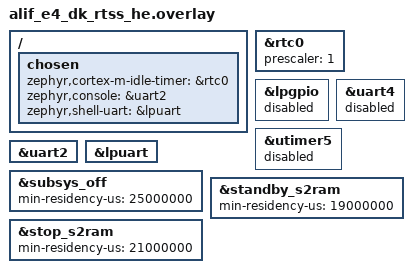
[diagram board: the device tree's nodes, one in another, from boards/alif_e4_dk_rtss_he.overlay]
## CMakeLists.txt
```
#
# Copyright (C) 2024  Alif Semiconductor
#
# SPDX-License-Identifier: Apache-2.0
#

cmake_minimum_required(VERSION 3.20.0)
find_package(Zephyr REQUIRED HINTS $ENV{ZEPHYR_BASE})
project(alif_system_off)

target_sources(app PRIVATE src/main.c)
```

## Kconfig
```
# Copyright (C) 2024 Alif Semiconductor - All Rights Reserved.
# Use, distribution and modification of this code is permitted under the
# terms stated in the Alif Semiconductor Software License Agreement
#
# You should have received a copy of the Alif Semiconductor Software
# License Agreement with this file. If not, please write to:
# contact@alifsemi.com, or visit: https://alifsemi.com/license


mainmenu "Alif Power Management States Demo"

source "Kconfig.zephyr"
```

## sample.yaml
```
sample:
  name: Alif Power Management States Demo
  description: >
    Demonstrates Zephyr power management states (PM_STATE_RUNTIME_IDLE,
    PM_STATE_SUSPEND_TO_IDLE, PM_STATE_SUSPEND_TO_RAM, PM_STATE_SOFT_OFF)
    for Alif RTSS cores.  The PM states exercised are driven by capability
    predicates (S2RAM_SUPPORTED / SOFT_OFF_SUPPORTED) rather than core type,
    and are selected via build snippets: pm-system-off-s2ram-tcm (HE TCM
    retention), pm-system-off-mram (MRAM boot SOFT_OFF, HE or HP), and
    pm-system-off-s2ram-sram0 (SRAM0 retention S2RAM, E8 only, HE or HP).
common:
  tags:
    - power
    - pm
    - counter
    - rtc
    - drivers
  filter: SOC_FAMILY_ENSEMBLE or SOC_FAMILY_BALLETTO
  harness: console
  harness_config:
    type: multi_line
    regex:
      - "PM states demo"
      - "POWER STATE SEQUENCE"
tests:
  sample.pm.system_off.s2ram_tcm:
    platform_allow:
      - alif_e7_dk_rtss_he
      - alif_e1c_dk_rtss_he
      - alif_b1_dk_rtss_he
      - alif_e8_dk_rtss_he
    integration_platforms:
      - alif_e7_dk_rtss_he
    depends_on:
      - counter
    extra_args:
      - SNIPPET=pm-system-off-s2ram-tcm
  sample.pm.system_off.mram:
    platform_allow:
      - alif_e7_dk_rtss_he
      - alif_e7_dk_rtss_hp
      - alif_e8_dk_rtss_he
      - alif_e8_dk_rtss_hp
      - alif_e1c_dk_rtss_he
      - alif_b1_dk_rtss_he
    integration_platforms:
      - alif_e7_dk_rtss_he
      - alif_e7_dk_rtss_hp
    depends_on:
      - counter
    extra_args:
      - SNIPPET=pm-system-off-mram
  sample.pm.system_off.s2ram_sram0:
    platform_allow:
      - alif_e8_dk_rtss_he
      - alif_e8_dk_rtss_hp
    integration_platforms:
      - alif_e8_dk_rtss_he
    depends_on:
      - counter
    extra_args:
      - SNIPPET=pm-system-off-s2ram-sram0
```

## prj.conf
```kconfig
CONFIG_PM=y
CONFIG_PM_DEVICE=y
CONFIG_POWER_DOMAIN=y
#CONFIG_POWEROFF=y
CONFIG_IDLE_STACK_SIZE=1024
CONFIG_SYS_CLOCK_TICKS_PER_SEC=1000

CONFIG_COUNTER=y

CONFIG_STDOUT_CONSOLE=y
CONFIG_PRINTK=y
CONFIG_ASSERT=y

# Logging Configuration - Only for this application
CONFIG_LOG=y
CONFIG_LOG_DEFAULT_LEVEL=0
CONFIG_LOG_MODE_DEFERRED=y
CONFIG_LOG_PROCESS_THREAD_SLEEP_MS=5
CONFIG_LOG_BACKEND_UART=y
```

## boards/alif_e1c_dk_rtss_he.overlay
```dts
/* Copyright (C) 2024 Alif Semiconductor - All Rights Reserved.
 * Use, distribution and modification of this code is permitted under the
 * terms stated in the Alif Semiconductor Software License Agreement
 *
 * You should have received a copy of the Alif Semiconductor Software
 * License Agreement with this file. If not, please write to:
 * contact@alifsemi.com, or visit: https: //alifsemi.com/license
 *
 */

&rtc0 {
	prescaler = <1>;
	status = "okay";
};

&lpgpio {
	status = "disabled";
};

&uart4 {
	status = "disabled";
};

&uart2 {
	status = "okay";
};

&lpuart {
	status = "okay";
};

&subsys_off {
	min-residency-us = <25000000>;
	status = "okay";
};

&standby_s2ram {
	min-residency-us = <19000000>;
	status = "okay";
};

&stop_s2ram {
	min-residency-us = <21000000>;
	status = "okay";
};

/ {
	chosen {
		zephyr,cortex-m-idle-timer = &rtc0;
		zephyr,console = &uart2;
		zephyr,shell-uart = &lpuart;
	};
};
```

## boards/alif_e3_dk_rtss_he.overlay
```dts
/*
 * Copyright (c) 2024 Alif Semiconductor
 * SPDX-License-Identifier: Apache-2.0
 */

/*
 * By default, the core boots from ITCM. Enable the below node to boot
 * from MRAM. Please make sure to use the same address in the json file
 * while flashing the binary using SE tools.
 */
/*
&itcm {
	reg = < 0x80000000 DT_SIZE_K(1024) >;
	itcm_global_base = < 0x80000000 >;
};
*/

/*
 * Enable RTC and Set the counter to increment every 1sec
 */
&rtc0 {
	prescaler = < 32768 >;
	status = "okay";
};
```

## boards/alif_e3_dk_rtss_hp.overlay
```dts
/* Copyright (C) 2025 Alif Semiconductor - All Rights Reserved.
 * Use, distribution and modification of this code is permitted under the
 * terms stated in the Alif Semiconductor Software License Agreement
 *
 * You should have received a copy of the Alif Semiconductor Software
 * License Agreement with this file. If not, please write to:
 * contact@alifsemi.com, or visit: https: //alifsemi.com/license
 *
 */

&timer0 {
	status = "okay";
};

&lpgpio {
	status = "disabled";
};

&uart4 {
	status = "disabled";
};

&utimer5 {
	status = "disabled";
};

&uart2 {
	status = "okay";
};

&subsys_off {
	min-residency-us = <25000000>;
	status = "okay";
};

/ {
	chosen {
		zephyr,console = &uart2;
	};
};
```

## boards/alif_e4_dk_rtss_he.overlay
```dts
/* Copyright (C) 2024 Alif Semiconductor - All Rights Reserved.
 * Use, distribution and modification of this code is permitted under the
 * terms stated in the Alif Semiconductor Software License Agreement
 *
 * You should have received a copy of the Alif Semiconductor Software
 * License Agreement with this file. If not, please write to:
 * contact@alifsemi.com, or visit: https: //alifsemi.com/license
 *
 */

&rtc0 {
	prescaler = <1>;
	status = "okay";
};

&lpgpio {
	status = "disabled";
};

&uart4 {
	status = "disabled";
};

&utimer5 {
	status = "disabled";
};

&uart2 {
	status = "okay";
};

&lpuart {
	status = "okay";
};

&subsys_off {
	min-residency-us = <25000000>;
	status = "okay";
};

&standby_s2ram {
	min-residency-us = <19000000>;
	status = "okay";
};

&stop_s2ram {
	min-residency-us = <21000000>;
	status = "okay";
};

/ {
	chosen {
		zephyr,cortex-m-idle-timer = &rtc0;
		zephyr,console = &uart2;
		zephyr,shell-uart = &lpuart;
	};
};
```

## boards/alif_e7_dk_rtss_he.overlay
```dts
/* Copyright (C) 2024 Alif Semiconductor - All Rights Reserved.
 * Use, distribution and modification of this code is permitted under the
 * terms stated in the Alif Semiconductor Software License Agreement
 *
 * You should have received a copy of the Alif Semiconductor Software
 * License Agreement with this file. If not, please write to:
 * contact@alifsemi.com, or visit: https: //alifsemi.com/license
 *
 */

/*
 * Enable RTC and Set the counter to increment every 1sec
 */
&rtc0 {
	prescaler = < 32768 >;
	status = "okay";
};
```

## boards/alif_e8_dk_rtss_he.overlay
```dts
/* Copyright (C) 2025 Alif Semiconductor - All Rights Reserved.
 * Use, distribution and modification of this code is permitted under the
 * terms stated in the Alif Semiconductor Software License Agreement
 *
 * You should have received a copy of the Alif Semiconductor Software
 * License Agreement with this file. If not, please write to:
 * contact@alifsemi.com, or visit: https: //alifsemi.com/license
 *
 */

&rtc0 {
	prescaler = <1>;
	status = "okay";
};

&lpgpio {
	status = "disabled";
};

&uart4 {
	status = "disabled";
};

&utimer5 {
	status = "disabled";
};

&uart2 {
	status = "okay";
};

&lpuart {
	status = "okay";
};

&subsys_off {
	min-residency-us = <25000000>;
	status = "okay";
};

&standby_s2ram {
	min-residency-us = <19000000>;
	status = "okay";
};

&stop_s2ram {
	min-residency-us = <21000000>;
	status = "okay";
};

/ {
	chosen {
		zephyr,cortex-m-idle-timer = &rtc0;
		zephyr,console = &uart2;
		zephyr,shell-uart = &lpuart;
	};
};
```

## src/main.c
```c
/* Copyright (C) 2024 Alif Semiconductor - All Rights Reserved.
 * Use, distribution and modification of this code is permitted under the
 * terms stated in the Alif Semiconductor Software License Agreement
 *
 * You should have received a copy of the Alif Semiconductor Software
 * License Agreement with this file. If not, please write to:
 * contact@alifsemi.com, or visit: https: //alifsemi.com/license
 *
 */

#include <stdio.h>
#include <zephyr/kernel.h>
#include <zephyr/device.h>
#include <zephyr/init.h>
#include <zephyr/pm/pm.h>
#include <zephyr/pm/policy.h>
#if defined(CONFIG_POWEROFF)
#include <zephyr/sys/poweroff.h>
#endif
#include <zephyr/drivers/counter.h>
#include <zephyr/sys/util.h>

#include <zephyr/logging/log.h>
LOG_MODULE_REGISTER(pm_system_off, LOG_LEVEL_INF);

/* Set to 1 to dump full NVIC ISPR state on wakeup */
#define APP_PM_WAKEUP_DEBUG 0

#if DT_NODE_HAS_COMPAT_STATUS(DT_NODELABEL(rtc0), snps_dw_apb_rtc, okay)
	#define WAKEUP_SOURCE DT_NODELABEL(rtc0)
#elif DT_NODE_HAS_COMPAT_STATUS(DT_NODELABEL(timer0), snps_dw_timers, okay)
	#define WAKEUP_SOURCE DT_NODELABEL(timer0)
#else
#error "Wakeup Device not enabled in the dts"
#endif


/*
 * Sleep duration constants for each PM state.
 *
 * Upper bound: at 400 MHz, ticks to cycles calculation in PM driver
 * overflows uint32 max for values > 10.7s (2^32 / 400). All deep-sleep
 * durations and overlay min-residency-us values must stay below this ceiling.
 */
/* Sleep duration for PM_STATE_RUNTIME_IDLE */
#define RUNTIME_IDLE_SLEEP_USEC (18 * 1000 * 1000)
/* Sleep duration for PM_STATE_SUSPEND_TO_IDLE */
#define SUSPEND_IDLE_SLEEP_USEC (10 * 1000)
/* Sleep duration for PM_STATE_SUSPEND_TO_RAM substate 0 (STANDBY) */
#define S2RAM_STANDBY_SLEEP_USEC (6 * 1000 * 1000)
/* Sleep duration for PM_STATE_SUSPEND_TO_RAM substate 1 (STOP) */
#define S2RAM_STOP_SLEEP_USEC (9 * 1000 * 1000)
/* Sleep duration for PM_STATE_SOFT_OFF */
#define SOFT_OFF_SLEEP_USEC (10 * 1000 * 1000)
/* Wakeup duration for sys_poweroff (permanent power off) */
#define POWEROFF_WAKEUP_USEC (10 * 1000 * 1000)

/*
 * MRAM base address - used to determine boot location
 * TCM boot: VTOR = 0x0
 * MRAM boot: VTOR >= 0x80000000
 */
#define MRAM_BASE_ADDRESS 0x80000000

#define IS_BOOTING_FROM_MRAM() (SCB->VTOR >= MRAM_BASE_ADDRESS)

/*
 * True when the DTS chosen zephyr,sram points at sram0. The snippet overlay
 * is responsible for ensuring SRAM0 has retention support on the target board.
 */
#if DT_NODE_EXISTS(DT_NODELABEL(sram0)) && DT_HAS_CHOSEN(zephyr_sram)
#define IS_SRAM0_CONFIGURED_AS_RAM() \
	DT_SAME_NODE(DT_CHOSEN(zephyr_sram), DT_NODELABEL(sram0))
#else
#define IS_SRAM0_CONFIGURED_AS_RAM() 0
#endif

/*
 * S2RAM_SUPPORTED — retention-capable sleep is possible when:
 *   - SRAM0 is the configured data RAM (HE or HP, E8 only), OR
 *   - HE core booting from TCM (TCM has hardware retention)
 *
 * SOFT_OFF_SUPPORTED — mutually exclusive with S2RAM: used when no
 * retained RAM is available (HP-TCM, HE-MRAM boot without SRAM0).
 */
#define S2RAM_SUPPORTED \
	(IS_SRAM0_CONFIGURED_AS_RAM() || \
	 (IS_ENABLED(CONFIG_RTSS_HE) && !IS_BOOTING_FROM_MRAM()))

#define SOFT_OFF_SUPPORTED (!S2RAM_SUPPORTED)

/* Validate ordering of deep-sleep durations at compile time */
BUILD_ASSERT(S2RAM_STOP_SLEEP_USEC > S2RAM_STANDBY_SLEEP_USEC,
	"STOP sleep duration must be greater than STANDBY sleep duration");
BUILD_ASSERT(SOFT_OFF_SLEEP_USEC > S2RAM_STOP_SLEEP_USEC,
	"SOFT_OFF sleep duration must be greater than STOP sleep duration");

/**
 * Helper function to lock/unlock deeper power states.
 * @param lock true → lock all deep states (allow RUNTIME_IDLE only)
 *             false → unlock the applicable state; keep the other locked
 */
static void app_pm_lock_deeper_states(bool lock)
{
	if (lock) {
		/*
		 * Lock both deep states unconditionally so PM policy cannot
		 * accidentally enter them during the RUNTIME_IDLE phase, where
		 * the 18 s sleep exceeds the reduced min-residency values.
		 */
		pm_policy_state_lock_get(PM_STATE_SUSPEND_TO_RAM, PM_ALL_SUBSTATES);
		pm_policy_state_lock_get(PM_STATE_SOFT_OFF,       PM_ALL_SUBSTATES);
	} else if (S2RAM_SUPPORTED) {
		pm_policy_state_lock_put(PM_STATE_SUSPEND_TO_RAM, PM_ALL_SUBSTATES);
		/* SOFT_OFF stays locked for the entire demo */
	} else {
		pm_policy_state_lock_put(PM_STATE_SOFT_OFF, PM_ALL_SUBSTATES);
		/* S2RAM stays locked for the entire demo */
	}
}

/*
 * This function will be invoked in the PRE_KERNEL_2 phase of the init routine.
 */
static int app_pre_kernel_init(void)
{
	/* Lock deeper power states to allow only RUNTIME_IDLE */
	app_pm_lock_deeper_states(true);

	return 0;
}
SYS_INIT(app_pre_kernel_init, PRE_KERNEL_2, 0);

#if !defined(CONFIG_CORTEX_M_SYSTICK_LPM_TIMER_COUNTER)
static volatile uint32_t alarm_cb_status;
static void alarm_callback_fn(const struct device *wakeup_dev,
				uint8_t chan_id, uint32_t ticks,
				void *user_data)
{
	LOG_DBG("%s: Alarm triggered", wakeup_dev->name);
	alarm_cb_status = 1;
}
#endif

static int app_enter_normal_sleep(uint32_t sleep_usec)
{
#if defined(CONFIG_CORTEX_M_SYSTICK_LPM_TIMER_COUNTER)
	k_sleep(K_USEC(sleep_usec));
#else
	const struct device *const wakeup_dev = DEVICE_DT_GET(WAKEUP_SOURCE);
	struct counter_alarm_cfg alarm_cfg;
	int ret;

	alarm_cfg.flags = 0;
	alarm_cfg.ticks = counter_us_to_ticks(wakeup_dev, sleep_usec);
	alarm_cfg.callback = alarm_callback_fn;
	alarm_cfg.user_data = &alarm_cfg;

	ret = counter_set_channel_alarm(wakeup_dev, 0, &alarm_cfg);
	if (ret) {
		LOG_ERR("Could not set the alarm");
		return ret;
	}
	LOG_DBG("Set alarm for %u microseconds", sleep_usec);

	k_sleep(K_USEC(sleep_usec));

	if (!alarm_cb_status) {
		return -1;
	}
	alarm_cb_status = 0;


#endif
	return 0;
}

#if !defined(CONFIG_POWEROFF)
static int app_enter_deep_sleep(uint32_t sleep_usec)
{
#if defined(CONFIG_CORTEX_M_SYSTICK_LPM_TIMER_COUNTER)
	/**
	 * Set a delay more than the min-residency-us configured so that
	 * the sub-system will go to OFF state.
	 */
	k_sleep(K_USEC(sleep_usec));
#else
	const struct device *const wakeup_dev = DEVICE_DT_GET(WAKEUP_SOURCE);
	struct counter_alarm_cfg alarm_cfg = {0};
	int ret;
	/*
	 * Set the alarm and delay so that idle thread can run
	 */
	alarm_cfg.ticks = counter_us_to_ticks(wakeup_dev, sleep_usec);
	alarm_cfg.callback = alarm_callback_fn;
	ret = counter_set_channel_alarm(wakeup_dev, 0, &alarm_cfg);
	if (ret) {
		LOG_ERR("Failed to set the alarm (err %d)", ret);
		return ret;
	}

	LOG_DBG("Set alarm for %u microseconds", sleep_usec);
	/*
	 * Wait for the alarm to trigger. The idle thread will
	 * take care of entering the deep sleep state via PM framework.
	 */
	k_sleep(K_USEC(sleep_usec));
#endif

	return 0;
}
#endif /* !CONFIG_POWEROFF */

/* PM state name lookup for notifier logging */
static const char * const pm_state_names[] = {
	[PM_STATE_ACTIVE]          = "ACTIVE",
	[PM_STATE_RUNTIME_IDLE]    = "RUNTIME_IDLE",
	[PM_STATE_SUSPEND_TO_IDLE] = "SUSPEND_TO_IDLE",
	[PM_STATE_STANDBY]         = "STANDBY",
	[PM_STATE_SUSPEND_TO_RAM]  = "SUSPEND_TO_RAM",
	[PM_STATE_SUSPEND_TO_DISK] = "SUSPEND_TO_DISK",
	[PM_STATE_SOFT_OFF]        = "SOFT_OFF",
};

#define PM_STATE_STR(s) \
	((s) < ARRAY_SIZE(pm_state_names) ? pm_state_names[(s)] : "UNKNOWN")

static void pm_notify_entry(enum pm_state state)
{
	const struct pm_state_info *info = pm_state_next_get(0);
	uint8_t substate_id = info ? info->substate_id : 0U;

	LOG_INF("PM enter: %s (substate %u)", PM_STATE_STR(state), substate_id);
}

/*
 * With CONFIG_LOG_MODE_DEFERRED, LOG_INF here only writes to the ring buffer
 * — no UART access — so this is safe even before devices are resumed.
 */
static void pm_notify_pre_resume(enum pm_state state)
{
	const struct pm_state_info *info = pm_state_next_get(0);
	uint8_t substate_id = info ? info->substate_id : 0U;
	uint32_t active_exc = SCB->ICSR & SCB_ICSR_VECTACTIVE_Msk;

	if (active_exc >= 16U) {
		LOG_INF("PM wakeup: %s (substate %u) IRQ %u",
			PM_STATE_STR(state), substate_id, active_exc - 16U);
	} else if (active_exc != 0U) {
		LOG_INF("PM wakeup: %s (substate %u) exception %u",
			PM_STATE_STR(state), substate_id, active_exc);
	} else {
		LOG_INF("PM wakeup: %s (substate %u)",
			PM_STATE_STR(state), substate_id);
	}
#if APP_PM_WAKEUP_DEBUG
	for (int i = 0; i < 16; i++) {
		if (NVIC->ISPR[i]) {
			LOG_INF("PM wakeup: NVIC ISPR[%d] = 0x%08x", i, NVIC->ISPR[i]);
		}
	}
#endif
}

static void pm_notify_exit(enum pm_state state)
{
	const struct pm_state_info *info = pm_state_next_get(0);
	uint8_t substate_id = info ? info->substate_id : 0U;

	LOG_INF("PM exit:  %s (substate %u)", PM_STATE_STR(state), substate_id);
}

static struct pm_notifier app_pm_notifier = {
	.state_entry       = pm_notify_entry,
	.pre_device_resume = pm_notify_pre_resume,
	.state_exit        = pm_notify_exit,
};

int main(void)
{
	const struct device *const cons = DEVICE_DT_GET(DT_CHOSEN(zephyr_console));
	const struct device *const wakeup_dev = DEVICE_DT_GET(WAKEUP_SOURCE);
	int ret;

	__ASSERT(device_is_ready(cons), "%s: device not ready", cons->name);
	__ASSERT(device_is_ready(wakeup_dev), "%s: device not ready", wakeup_dev->name);

	pm_notifier_register(&app_pm_notifier);

	if (S2RAM_SUPPORTED) {
		LOG_INF("%s (S2RAM): PM states demo "
			"(RUNTIME_IDLE, SUSPEND_TO_IDLE, S2RAM STANDBY, S2RAM STOP)",
			CONFIG_BOARD);
	} else {
		LOG_INF("%s (SOFT_OFF): PM states demo "
			"(RUNTIME_IDLE, SUSPEND_TO_IDLE, SOFT_OFF)",
			CONFIG_BOARD);
	}

	ret = counter_start(wakeup_dev);
	__ASSERT(!ret || ret == -EALREADY, "Failed to start counter (err %d)", ret);

	LOG_INF("POWER STATE SEQUENCE:");
#if defined(CONFIG_POWEROFF)
	LOG_INF("  1. PM_STATE_RUNTIME_IDLE");
	LOG_INF("  2. PM_STATE_SUSPEND_TO_IDLE");
	LOG_INF("  3. Power off (sys_poweroff)");
#else
	LOG_INF("  1. PM_STATE_RUNTIME_IDLE");
	LOG_INF("  2. PM_STATE_SUSPEND_TO_IDLE");
	if (S2RAM_SUPPORTED) {
		LOG_INF("  3. PM_STATE_SUSPEND_TO_RAM (substate 0: STANDBY)");
		LOG_INF("  4. PM_STATE_SUSPEND_TO_RAM (substate 1: STOP)");
	} else {
		LOG_INF("  3. PM_STATE_SOFT_OFF");
	}
#endif

	/* Lock SUSPEND_IDLE to force PM policy to select RUNTIME_IDLE only */
	pm_policy_state_lock_get(PM_STATE_SUSPEND_TO_IDLE, PM_ALL_SUBSTATES);
	LOG_INF("Enter RUNTIME_IDLE sleep for (%d microseconds)", RUNTIME_IDLE_SLEEP_USEC);
	ret = app_enter_normal_sleep(RUNTIME_IDLE_SLEEP_USEC);
	__ASSERT(ret == 0, "Could not enter RUNTIME_IDLE sleep (err %d)", ret);

	LOG_INF("Exited from RUNTIME_IDLE sleep");
	pm_policy_state_lock_put(PM_STATE_SUSPEND_TO_IDLE, PM_ALL_SUBSTATES);

#if defined(CONFIG_CORTEX_M_SYSTICK_LPM_TIMER_COUNTER)
	LOG_INF("Enter PM_STATE_SUSPEND_TO_IDLE for (%d microseconds)",
		SUSPEND_IDLE_SLEEP_USEC);
	k_sleep(K_USEC(SUSPEND_IDLE_SLEEP_USEC));
	LOG_INF("Exited from PM_STATE_SUSPEND_TO_IDLE");
	pm_policy_state_lock_get(PM_STATE_SUSPEND_TO_IDLE, PM_ALL_SUBSTATES);
#else
	/* Lock SUSPEND_TO_IDLE when LPM timer support is not configured */
	pm_policy_state_lock_get(PM_STATE_SUSPEND_TO_IDLE, PM_ALL_SUBSTATES);
	LOG_INF("PM_STATE_SUSPEND_TO_IDLE (skipped - LPM timer not enabled)");
#endif

#if defined(CONFIG_POWEROFF)
	/* Configure wakeup source for permanent power off */
	struct counter_alarm_cfg alarm_cfg;

	LOG_INF("=== Enter (sys_poweroff) ===");
	LOG_INF("System will power off and can only wake via external event (RTC/Timer)");
	k_sleep(K_SECONDS(2));

	/* Set alarm for wakeup from power off */
	alarm_cfg.ticks = counter_us_to_ticks(wakeup_dev, POWEROFF_WAKEUP_USEC);
	ret = counter_set_channel_alarm(wakeup_dev, 0, &alarm_cfg);
	if (ret) {
		LOG_ERR("Failed to set wakeup alarm (err %d)", ret);
	} else {
		LOG_INF("Wakeup alarm set for %u seconds", POWEROFF_WAKEUP_USEC / 1000000);
	}

	LOG_INF("Calling sys_poweroff() - system will power off permanently");
	sys_poweroff();

	/* Should never reach here */
	LOG_ERR("Failed to execute sys_poweroff()");

	return -1;
#else
	/* Unlock deeper power states to allow S2RAM and/or SOFT_OFF */
	app_pm_lock_deeper_states(false);

	if (S2RAM_SUPPORTED) {
		LOG_INF("Enter PM_STATE_SUSPEND_TO_RAM (substate 0: STANDBY) for (%d microseconds)",
			S2RAM_STANDBY_SLEEP_USEC);
		ret = app_enter_deep_sleep(S2RAM_STANDBY_SLEEP_USEC);
		__ASSERT(ret == 0, "Could not enter PM_STATE_SUSPEND_TO_RAM (err %d)", ret);

		LOG_INF("=== Resumed from PM_STATE_SUSPEND_TO_RAM (substate 0: STANDBY) ===");

		for (int i = 0; i < 3; i++) {
			LOG_INF("Main thread running - iteration %d - tick: %llu",
				i, k_uptime_ticks());
			k_sleep(K_SECONDS(2));
		}

		LOG_INF("Enter PM_STATE_SUSPEND_TO_RAM (substate 1: STOP) for (%d microseconds)",
			S2RAM_STOP_SLEEP_USEC);
		ret = app_enter_deep_sleep(S2RAM_STOP_SLEEP_USEC);
		__ASSERT(ret == 0, "Could not enter PM_STATE_SUSPEND_TO_RAM (err %d)", ret);

		LOG_INF("=== Resumed from PM_STATE_SUSPEND_TO_RAM (substate 1: STOP) ===");

		for (int i = 0; i < 3; i++) {
			LOG_INF("Main thread running - iteration %d - tick: %llu",
				i, k_uptime_ticks());
			k_sleep(K_SECONDS(2));
		}
	}

	if (SOFT_OFF_SUPPORTED) {
		LOG_INF("Enter PM_STATE_SOFT_OFF for (%d microseconds)", SOFT_OFF_SLEEP_USEC);
		LOG_INF("Note: SOFT_OFF has no retention - system will reset on wakeup");
		ret = app_enter_deep_sleep(SOFT_OFF_SLEEP_USEC);
		__ASSERT(ret == 0, "Could not enter PM_STATE_SOFT_OFF (err %d)", ret);

		/* Should never reach here - SOFT_OFF causes full reset on wakeup */
		LOG_ERR("ERROR: Resumed after PM_STATE_SOFT_OFF - this should not happen!");
		__ASSERT(false, "PM_STATE_SOFT_OFF should have caused a reset");
	}

	LOG_INF("=== POWER STATE SEQUENCE COMPLETED ===");

	app_pm_lock_deeper_states(true);

	while (true) {
		/* spin here */
		k_sleep(K_SECONDS(1));
	}
#endif

	return 0;
}
```
